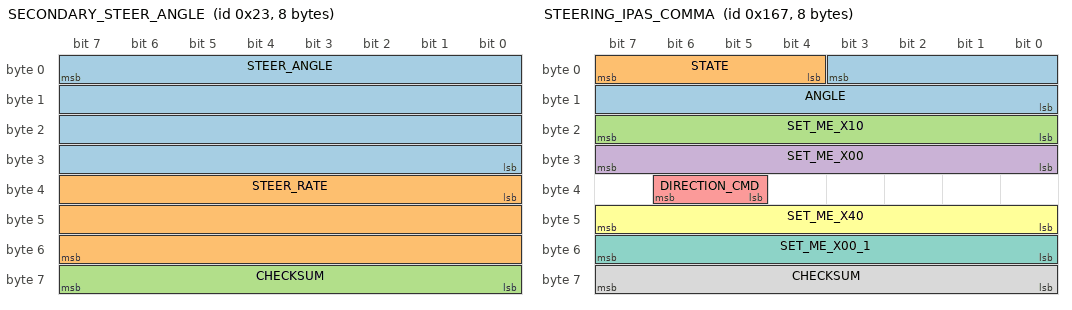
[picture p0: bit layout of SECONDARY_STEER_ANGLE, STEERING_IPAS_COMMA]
BO_ 35 SECONDARY_STEER_ANGLE: 8 XXX
 SG_ STEER_ANGLE : 7|32@0- (0.00485601697,0) [0|500] "" XXX
 SG_ STEER_RATE : 32|24@1- (0.00485601697,0) [0|16777215] "" XXX
 SG_ CHECKSUM : 63|8@0+ (1,0) [0|255] "" XXX

BO_ 359 STEERING_IPAS_COMMA: 8 IPAS
 SG_ ANGLE : 3|12@0- (1.5,0) [-510|510] "deg" XXX
 SG_ STATE : 7|4@0+ (1,0) [0|15] "" XXX
 SG_ SET_ME_X10 : 23|8@0+ (1,0) [0|255] "" XXX
 SG_ SET_ME_X00 : 31|8@0+ (1,0) [0|255] "" XXX
 SG_ DIRECTION_CMD : 38|2@0+ (1,0) [0|3] "" XXX
 SG_ SET_ME_X40 : 47|8@0+ (1,0) [0|255] "" XXX
 SG_ SET_ME_X00_1 : 55|8@0+ (1,0) [0|255] "" XXX
 SG_ CHECKSUM : 63|8@0+ (1,0) [0|255] "" XXX

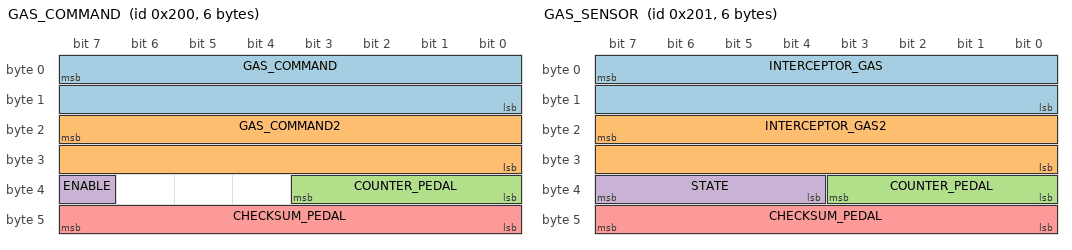
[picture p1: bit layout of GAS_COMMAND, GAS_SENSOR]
BO_ 512 GAS_COMMAND: 6 EON
 SG_ GAS_COMMAND : 7|16@0+ (0.159375,-75.555) [0|1] "" INTERCEPTOR
 SG_ GAS_COMMAND2 : 23|16@0+ (0.159375,-151.111) [0|1] "" INTERCEPTOR
 SG_ COUNTER_PEDAL : 35|4@0+ (1,0) [0|15] "" INTERCEPTOR
 SG_ ENABLE : 39|1@0+ (1,0) [0|1] "" INTERCEPTOR
 SG_ CHECKSUM_PEDAL : 47|8@0+ (1,0) [0|255] "" INTERCEPTOR

BO_ 513 GAS_SENSOR: 6 INTERCEPTOR
 SG_ INTERCEPTOR_GAS : 7|16@0+ (1,0) [0|1] "" EON
 SG_ INTERCEPTOR_GAS2 : 23|16@0+ (1,0) [0|1] "" EON
 SG_ COUNTER_PEDAL : 35|4@0+ (1,0) [0|15] "" EON
 SG_ STATE : 39|4@0+ (1,0) [0|15] "" EON
 SG_ CHECKSUM_PEDAL : 47|8@0+ (1,0) [0|255] "" EON

BO_ 767 SDSU: 8 XXX
 SG_ FD_BUTTON : 7|1@0+ (1,0) [0|1] "" XXX
 SG_ STATE : 23|4@0+ (1,0) [0|15] "" XXX

CM_ SG_ 767 FD_BUTTON "The follow distance button signal as forwarded by the sdsu";
VAL_ 513 STATE 5 "FAULT_TIMEOUT" 4 "FAULT_STARTUP" 3 "FAULT_SCE" 2 "FAULT_SEND" 1 "FAULT_BAD_CHECKSUM" 0 "NO_FAULT";
VAL_ 767 STATE 7 "STATE_AEB_CTRL" 6 "FAULT_INVALID" 5 "FAULT_TIMEOUT" 4 "FAULT_STARTUP" 3 "FAULT_SCE" 2 "FAULT_SEND" 1 "FAULT_BAD_CHECKSUM" 0 "NO_FAULT";
